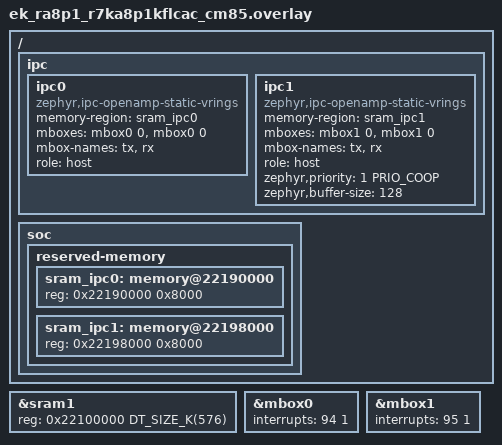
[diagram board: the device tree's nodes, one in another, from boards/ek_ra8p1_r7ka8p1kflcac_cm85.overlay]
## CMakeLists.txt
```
#
# Copyright (c) 2021 Carlo Caione <ccaione@baylibre.com>
# Copyright 2024-2026 NXP
#
# SPDX-License-Identifier: Apache-2.0
#

cmake_minimum_required(VERSION 3.28.0)

find_package(Zephyr REQUIRED HINTS $ENV{ZEPHYR_BASE})

if(CONFIG_INCLUDE_REMOTE_DIR)
set(REMOTE_ZEPHYR_DIR ${CMAKE_CURRENT_BINARY_DIR}/../remote/zephyr)
endif()

if(NOT (CONFIG_BOARD_NRF5340DK_NRF5340_CPUAPP OR
        CONFIG_BOARD_NRF5340BSIM_NRF5340_CPUAPP OR
        CONFIG_BOARD_LPCXPRESSO55S69_LPC55S69_CPU0 OR
        CONFIG_BOARD_MIMXRT1160_EVK_MIMXRT1166_CM7 OR
        CONFIG_BOARD_MIMXRT1170_EVK_MIMXRT1176_CM7 OR
        CONFIG_BOARD_MIMXRT700_EVK_MIMXRT798S_CM33_CPU0 OR
        CONFIG_BOARD_FRDM_IMXRT700_MIMXRT798S_CM33_CPU0 OR
        CONFIG_BOARD_FRDM_MCXN947_MCXN947_CPU0 OR
        CONFIG_BOARD_MCX_N9XX_EVK_MCXN947_CPU0 OR
        CONFIG_BOARD_MIMXRT1180_EVK_MIMXRT1189_CM33 OR
        CONFIG_BOARD_FRDM_IMXRT1186_MIMXRT1186_CM33 OR
        CONFIG_BOARD_EK_RA8P1_R7KA8P1KFLCAC_CM85
       )
  )
  message("${BOARD} is not supported for this sample")
endif()


project(ipc_service)

if(CONFIG_INCLUDE_REMOTE_DIR)
  target_include_directories(zephyr_interface
    INTERFACE ${REMOTE_ZEPHYR_DIR}/include/public)
endif()

target_sources(app PRIVATE src/main.c)

include(ExternalProject)
```

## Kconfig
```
# Copyright 2024 NXP
#
# SPDX-License-Identifier: Apache-2.0

source "Kconfig.zephyr"

config INCLUDE_REMOTE_DIR
	bool "Include remote core header directory"
	help
	  Include remote build header files. Can be used if primary image
	  needs to be aware of size or base address of secondary image
```

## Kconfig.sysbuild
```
# Copyright 2023 Nordic Semiconductor ASA
# Copyright 2024-2026 NXP
#
# SPDX-License-Identifier: Apache-2.0

source "share/sysbuild/Kconfig"

config NET_CORE_BOARD
string
	default "nrf5340dk/nrf5340/cpunet" if $(BOARD) = "nrf5340dk"
	default "nrf5340bsim/nrf5340/cpunet" if $(BOARD) = "nrf5340bsim"
	default "lpcxpresso55s69/lpc55s69/cpu1" if $(BOARD) = "lpcxpresso55s69"
	default "mimxrt1160_evk/mimxrt1166/cm4" if $(BOARD) = "mimxrt1160_evk"
	default "mimxrt1170_evk/mimxrt1176/cm4" if $(BOARD) = "mimxrt1170_evk"
	default "mimxrt1170_evkb/mimxrt1176/cm4" if $(BOARD) = "mimxrt1170_evkb"
	default "mimxrt700_evk/mimxrt798s/cm33_cpu1" if $(BOARD) = "mimxrt700_evk"
	default "frdm_mcxn947/mcxn947/cpu1" if $(BOARD) = "frdm_mcxn947"
	default "mcx_n9xx_evk/mcxn947/cpu1" if $(BOARD) = "mcx_n9xx_evk"
	default "mimxrt1180_evk/mimxrt1189/cm7" if "$(BOARD)/$(BOARD_QUALIFIERS)" = "mimxrt1180_evk/mimxrt1189/cm33"
	default "frdm_imxrt1186/mimxrt1186/cm7" if $(BOARD) = "frdm_imxrt1186"
	default "frdm_imxrt700/mimxrt798s/cm33_cpu1" if $(BOARD) = "frdm_imxrt700"
	default "ek_ra8p1/r7ka8p1kflcac/cm33" if $(BOARD) = "ek_ra8p1"
	default "imx943_evk/mimx94398/m33" if "$(BOARD)/$(BOARD_QUALIFIERS)" = "imx943_evk/mimx94398/m7_1"
	default "imx943_evk/mimx94398/m33" if "$(BOARD)/$(BOARD_QUALIFIERS)" = "imx943_evk/mimx94398/m7_0"
	default "imx943_evk/mimx94398/m7_1" if "$(BOARD)/$(BOARD_QUALIFIERS)" = "imx943_evk/mimx94398/m33"
```

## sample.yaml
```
sample:
  name: IPC Service example integration (OpenAMP static_vrings backend)
tests:
  sample.ipc.static_vrings:
    filter: dt_compat_enabled("zephyr,ipc-openamp-static-vrings") and
            dt_nodelabel_enabled("ipc0") and dt_nodelabel_enabled("ipc1")
    platform_exclude:
      - nrf5340dk/nrf5340/cpuapp/ns
      - nrf5340dk/nrf5340/cpunet
    integration_platforms:
      - nrf5340dk/nrf5340/cpuapp
      - nrf5340bsim/nrf5340/cpuapp
    tags: ipc
    sysbuild: true
    harness: console
    harness_config:
      type: multi_line
      ordered: false
      regex:
        - "IPC-service HOST \\[INST 0 - ENDP A\\] demo started"
        - "IPC-service HOST \\[INST 0 - ENDP B\\] demo started"
        - "IPC-service HOST \\[INST 1\\] demo started"
        - "IPC-service HOST \\[INST 0 - ENDP A\\] demo ended\\."
        - "IPC-service HOST \\[INST 0 - ENDP B\\] demo ended\\."
        - "IPC-service HOST \\[INST 1\\] demo ended\\."
```

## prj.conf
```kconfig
CONFIG_PRINTK=y
CONFIG_HEAP_MEM_POOL_SIZE=4096

CONFIG_IPC_SERVICE=y
CONFIG_MBOX=y

CONFIG_OPENAMP=y
CONFIG_OPENAMP_SLAVE=n

CONFIG_LOG=y
CONFIG_LOG_BUFFER_SIZE=4096
CONFIG_IPC_SERVICE_LOG_LEVEL_INF=y
```

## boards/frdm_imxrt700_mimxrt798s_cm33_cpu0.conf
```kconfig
# SPDX-FileCopyrightText: Copyright 2026 NXP
# SPDX-License-Identifier: Apache-2.0

CONFIG_SECOND_CORE_MCUX=y
CONFIG_INCLUDE_REMOTE_DIR=y
CONFIG_DCACHE=n
```

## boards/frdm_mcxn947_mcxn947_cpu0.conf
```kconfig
CONFIG_SECOND_CORE_MCUX=y
```

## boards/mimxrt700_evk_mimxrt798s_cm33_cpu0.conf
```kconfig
#
# Copyright 2025 NXP
#
# SPDX-License-Identifier: Apache-2.0
#

CONFIG_SECOND_CORE_MCUX=y
CONFIG_INCLUDE_REMOTE_DIR=y
CONFIG_DCACHE=n
```

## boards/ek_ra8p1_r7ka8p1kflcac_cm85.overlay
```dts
/*
 * Copyright (c) 2025-2026 Renesas Electronics Corporation
 * SPDX-License-Identifier: Apache-2.0
 */

#include <zephyr/dt-bindings/ipc_service/static_vrings.h>

/ {
	ipc {
		ipc0: ipc0 {
			compatible = "zephyr,ipc-openamp-static-vrings";
			memory-region = <&sram_ipc0>;
			mboxes = <&mbox0 0>, <&mbox0 0>;
			mbox-names = "tx", "rx";
			role = "host";
			status = "okay";
		};

		ipc1: ipc1 {
			compatible = "zephyr,ipc-openamp-static-vrings";
			memory-region = <&sram_ipc1>;
			mboxes = <&mbox1 0>, <&mbox1 0>;
			mbox-names = "tx", "rx";
			role = "host";
			zephyr,priority = <1 PRIO_COOP>;
			zephyr,buffer-size = <128>;
			status = "okay";
		};
	};

	soc {
		/* Define shared memory regions for IPC */
		reserved-memory {
			#address-cells = <1>;
			#size-cells = <1>;

			sram_ipc0: memory@22190000 {
				reg = <0x22190000 0x8000>;
			};

			sram_ipc1: memory@22198000 {
				reg = <0x22198000 0x8000>;
			};
		};
	};
};

/* Redefine sram size for CPU1 */
&sram1 {
	reg = <0x22100000 DT_SIZE_K(576)>;
};

&mbox0 {
	interrupts = <94 1>;
	status = "okay";
};

&mbox1 {
	interrupts = <95 1>;
	status = "okay";
};
```

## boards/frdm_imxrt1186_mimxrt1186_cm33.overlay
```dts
/*
 * Copyright 2026 NXP
 *
 * SPDX-License-Identifier: Apache-2.0
 */

#include <zephyr/dt-bindings/ipc_service/static_vrings.h>
#include <zephyr/dt-bindings/memory-attr/memory-attr-arm.h>

/ {
	ipc {
		/delete-node/ ipc0;

		ipc0: ipc0 {
			compatible = "zephyr,ipc-openamp-static-vrings";
			memory-region = <&ocram2_ipc0>;
			mboxes = <&mbox1_a 0>, <&mbox1_a 1>;
			mbox-names = "tx", "rx";
			role = "host";
			status = "okay";
		};

		ipc1: ipc1 {
			compatible = "zephyr,ipc-openamp-static-vrings";
			memory-region = <&ocram2_ipc1>;
			mboxes = <&mbox1_a 2>, <&mbox1_a 3>;
			mbox-names = "tx", "rx";
			role = "host";
			zephyr,priority = <1 PRIO_COOP>;
			zephyr,buffer-size = <128>;
			status = "okay";
		};
	};

	/* Define memory regions for IPC */
	ocram2_ipc0: memory@20500000 {
		compatible = "zephyr,memory-region", "mmio-sram";
		reg = <0x20500000 DT_SIZE_K(16)>;
		zephyr,memory-region = "OCRAM2_IPC0";
		zephyr,memory-attr = <DT_MEM_ARM(ATTR_MPU_IO)>;
	};

	ocram2_ipc1: memory@20504000 {
		compatible = "zephyr,memory-region", "mmio-sram";
		reg = <0x20504000 DT_SIZE_K(16)>;
		zephyr,memory-region = "OCRAM2_IPC1";
		zephyr,memory-attr = <DT_MEM_ARM(ATTR_MPU_IO)>;
	};
};
```

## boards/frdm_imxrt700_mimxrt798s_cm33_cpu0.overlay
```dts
/*
 * SPDX-FileCopyrightText: Copyright 2026 NXP
 *
 * SPDX-License-Identifier: Apache-2.0
 */

#include <zephyr/dt-bindings/ipc_service/static_vrings.h>
#include <zephyr/dt-bindings/memory-attr/memory-attr-arm.h>

/ {
	/* Define memory regions for IPC */
	sram1_ipc0: memory@20200000 {
		compatible = "zephyr,memory-region", "mmio-sram";
		reg = <0x20200000 DT_SIZE_K(16)>;
		zephyr,memory-region = "SRAM1_IPC0";
		zephyr,memory-attr = <DT_MEM_ARM(ATTR_MPU_IO)>;
	};

	sram1_ipc1: memory@20204000 {
		compatible = "zephyr,memory-region", "mmio-sram";
		reg = <0x20204000 DT_SIZE_K(16)>;
		zephyr,memory-region = "SRAM1_IPC1";
		zephyr,memory-attr = <DT_MEM_ARM(ATTR_MPU_IO)>;
	};

	ipc {
		/delete-node/ ipc0;

		ipc0: ipc0 {
			compatible = "zephyr,ipc-openamp-static-vrings";
			memory-region = <&sram1_ipc0>;
			mboxes = <&mbox1_a 0>, <&mbox1_a 1>;
			mbox-names = "tx", "rx";
			role = "host";
			status = "okay";
		};

		ipc1: ipc1 {
			compatible = "zephyr,ipc-openamp-static-vrings";
			memory-region = <&sram1_ipc1>;
			mboxes = <&mbox1_a 2>, <&mbox1_a 3>;
			mbox-names = "tx", "rx";
			role = "host";
			zephyr,priority = <1 PRIO_COOP>;
			zephyr,buffer-size = <128>;
			status = "okay";
		};
	};
};
```

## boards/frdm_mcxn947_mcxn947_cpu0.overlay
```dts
/*
 * Copyright 2024 NXP
 *
 * SPDX-License-Identifier: Apache-2.0
 */

#include <zephyr/dt-bindings/ipc_service/static_vrings.h>
#include <zephyr/dt-bindings/memory-attr/memory-attr-arm.h>

/ {
	ipc {
		/delete-node/ ipc0;

		ipc0: ipc0 {
			compatible = "zephyr,ipc-openamp-static-vrings";
			memory-region = <&sram1_ipc0>;
			mboxes = <&mbox 0>, <&mbox 1>;
			mbox-names = "tx", "rx";
			role = "host";
			status = "okay";
		};

		ipc1: ipc1 {
			compatible = "zephyr,ipc-openamp-static-vrings";
			memory-region = <&sram1_ipc1>;
			mboxes = <&mbox 2>, <&mbox 3>;
			mbox-names = "tx", "rx";
			role = "host";
			zephyr,priority = <1 PRIO_COOP>;
			zephyr,buffer-size = <128>;
			status = "okay";
		};
	};

	/* Define memory regions for IPC
	 * Note that shared memory must have specific MPU attributes set.
	 */
	sram1_ipc0: memory@20060000 {
		compatible = "zephyr,memory-region", "mmio-sram";
		reg = <0x20060000 DT_SIZE_K(16)>;
		zephyr,memory-region = "SRAM1_IPC0";
		zephyr,memory-attr = <DT_MEM_ARM(ATTR_MPU_IO)>;
	};

	sram1_ipc1: memory@20064000 {
		compatible = "zephyr,memory-region", "mmio-sram";
		reg = <0x20064000 DT_SIZE_K(16)>;
		zephyr,memory-region = "SRAM1_IPC1";
		zephyr,memory-attr = <DT_MEM_ARM(ATTR_MPU_IO)>;
	};
};
```

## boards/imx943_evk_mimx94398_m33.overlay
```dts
/*
 * Copyright 2025 NXP
 *
 * SPDX-License-Identifier: Apache-2.0
 */

#include <zephyr/dt-bindings/ipc_service/static_vrings.h>
#include <zephyr/dt-bindings/memory-attr/memory-attr-arm.h>

/ {
	ipc {
		ipc0: ipc0 {
			compatible = "zephyr,ipc-openamp-static-vrings";
			memory-region = <&dram_m33s_m71_ipc0>;
			mboxes = <&mu_m33s_m71_for_m33s 0>, <&mu_m33s_m71_for_m33s 1>;
			mbox-names = "tx", "rx";
			role = "host";
			status = "okay";
		};

		ipc1: ipc1 {
			compatible = "zephyr,ipc-openamp-static-vrings";
			memory-region = <&dram_m33s_m71_ipc1>;
			mboxes = <&mu_m33s_m71_for_m33s 2>, <&mu_m33s_m71_for_m33s 3>;
			mbox-names = "tx", "rx";
			role = "host";
			zephyr,priority = <1 PRIO_COOP>;
			zephyr,buffer-size = <128>;
			status = "okay";
		};
	};
};
```

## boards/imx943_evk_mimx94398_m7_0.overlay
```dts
/*
 * Copyright 2025 NXP
 *
 * SPDX-License-Identifier: Apache-2.0
 */

#include <zephyr/dt-bindings/ipc_service/static_vrings.h>
#include <zephyr/dt-bindings/memory-attr/memory-attr-arm.h>

/ {
	ipc {
		ipc0: ipc0 {
			compatible = "zephyr,ipc-openamp-static-vrings";
			memory-region = <&dram_m33s_m70_ipc0>;
			mboxes = <&mu_m33s_m70_for_m70 0>, <&mu_m33s_m70_for_m70 1>;
			mbox-names = "tx", "rx";
			role = "host";
			status = "okay";
		};

		ipc1: ipc1 {
			compatible = "zephyr,ipc-openamp-static-vrings";
			memory-region = <&dram_m33s_m70_ipc1>;
			mboxes = <&mu_m33s_m70_for_m70 2>, <&mu_m33s_m70_for_m70 3>;
			mbox-names = "tx", "rx";
			role = "host";
			zephyr,priority = <1 PRIO_COOP>;
			zephyr,buffer-size = <128>;
			status = "okay";
		};
	};
};
```

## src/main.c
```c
/*
 * Copyright (c) 2021 Carlo Caione <ccaione@baylibre.com>
 *
 * SPDX-License-Identifier: Apache-2.0
 */

#include <zephyr/kernel.h>
#include <zephyr/device.h>

#include <zephyr/ipc/ipc_service.h>

#define STACKSIZE	(4096)
#define PRIORITY	K_PRIO_PREEMPT(2)

K_THREAD_STACK_DEFINE(ipc0A_stack, STACKSIZE);
K_THREAD_STACK_DEFINE(ipc0B_stack, STACKSIZE);
K_THREAD_STACK_DEFINE(ipc1_stack, STACKSIZE);

static volatile uint8_t ipc0A_received_data;
static volatile uint8_t ipc0B_received_data;
static volatile uint8_t ipc1_received_data;

static K_SEM_DEFINE(ipc0A_bound_sem, 0, 1);
static K_SEM_DEFINE(ipc0B_bound_sem, 0, 1);
static K_SEM_DEFINE(ipc1_bound_sem, 0, 1);

static K_SEM_DEFINE(ipc0A_data_sem, 0, 1);
static K_SEM_DEFINE(ipc0B_data_sem, 0, 1);
static K_SEM_DEFINE(ipc1_data_sem, 0, 1);

/*
 * ==> THREAD 0A (IPC instance 0 - endpoint A) <==
 */

static void ipc0A_ept_bound(void *priv)
{
	k_sem_give(&ipc0A_bound_sem);
}

static void ipc0A_ept_recv(const void *data, size_t len, void *priv)
{
	ipc0A_received_data = *((uint8_t *) data);

	k_sem_give(&ipc0A_data_sem);
}

static struct ipc_ept_cfg ipc0A_ept_cfg = {
	.name = "ipc0A",
	.cb = {
		.bound    = ipc0A_ept_bound,
		.received = ipc0A_ept_recv,
	},
};

static void ipc0A_entry(void *dummy0, void *dummy1, void *dummy2)
{
	ARG_UNUSED(dummy0);
	ARG_UNUSED(dummy1);
	ARG_UNUSED(dummy2);

	const struct device *ipc0_instance;
	unsigned char message = 0;
	struct ipc_ept ipc0A_ept;
	int ret;

	printk("IPC-service HOST [INST 0 - ENDP A] demo started\n");

	ipc0_instance = DEVICE_DT_GET(DT_NODELABEL(ipc0));

	ret = ipc_service_open_instance(ipc0_instance);
	if (ret < 0 && ret != -EALREADY) {
		printk("ipc_service_open_instance() failure\n");
		return;
	}

	/*
	 * Wait 1 sec to give the opportunity to the SECONDARY core to register
	 * the endpoint first
	 */

	k_sleep(K_MSEC(1000));

	ret = ipc_service_register_endpoint(ipc0_instance, &ipc0A_ept, &ipc0A_ept_cfg);
	if (ret < 0) {
		printf("ipc_service_register_endpoint() failure\n");
		return;
	}

	k_sem_take(&ipc0A_bound_sem, K_FOREVER);

	while (message < 100) {
		ret = ipc_service_send(&ipc0A_ept, &message, sizeof(message));
		if (ret < 0) {
			printk("send_message(%d) failed with ret %d\n", message, ret);
			break;
		}

		k_sem_take(&ipc0A_data_sem, K_FOREVER);
		message = ipc0A_received_data;

		printk("HOST [0A]: %d\n", message);
		message++;
	}

	printk("IPC-service HOST [INST 0 - ENDP A] demo ended.\n");
}
K_THREAD_DEFINE(ipc0A_thread_id, STACKSIZE, ipc0A_entry, NULL, NULL, NULL, PRIORITY, 0, 0);

/*
 * ==> THREAD 0B (IPC instance 0 - endpoint B) <==
 */

static void ipc0B_ept_bound(void *priv)
{
	k_sem_give(&ipc0B_bound_sem);
}

static void ipc0B_ept_recv(const void *data, size_t len, void *priv)
{
	ipc0B_received_data = *((uint8_t *) data);

	k_sem_give(&ipc0B_data_sem);
}

static struct ipc_ept_cfg ipc0B_ept_cfg = {
	.name = "ipc0B",
	.cb = {
		.bound    = ipc0B_ept_bound,
		.received = ipc0B_ept_recv,
	},
};

static void ipc0B_entry(void *dummy0, void *dummy1, void *dummy2)
{
	ARG_UNUSED(dummy0);
	ARG_UNUSED(dummy1);
	ARG_UNUSED(dummy2);

	const struct device *ipc0_instance;
	unsigned char message = 0;
	struct ipc_ept ipc0B_ept;
	int ret;

	printk("IPC-service HOST [INST 0 - ENDP B] demo started\n");

	ipc0_instance = DEVICE_DT_GET(DT_NODELABEL(ipc0));

	ret = ipc_service_open_instance(ipc0_instance);
	if (ret < 0 && ret != -EALREADY) {
		printk("ipc_service_open_instance() failure\n");
		return;
	}

	ret = ipc_service_register_endpoint(ipc0_instance, &ipc0B_ept, &ipc0B_ept_cfg);
	if (ret < 0) {
		printf("ipc_service_register_endpoint() failure\n");
		return;
	}

	k_sem_take(&ipc0B_bound_sem, K_FOREVER);

	while (message < 100) {
		ret = ipc_service_send(&ipc0B_ept, &message, sizeof(message));
		if (ret < 0) {
			printk("send_message(%d) failed with ret %d\n", message, ret);
			break;
		}

		k_sem_take(&ipc0B_data_sem, K_FOREVER);
		message = ipc0B_received_data;

		printk("HOST [0B]: %d\n", message);
		message++;
	}

	printk("IPC-service HOST [INST 0 - ENDP B] demo ended.\n");
}
K_THREAD_DEFINE(ipc0B_thread_id, STACKSIZE, ipc0B_entry, NULL, NULL, NULL, PRIORITY, 0, 0);

/*
 * ==> THREAD 1 (IPC instance 1) <==
 *
 * NOTE: This instance is using the NOCOPY copability of the backend.
 */

static struct ipc_ept ipc1_ept;
static void *recv_data;

static void ipc1_ept_bound(void *priv)
{
	k_sem_give(&ipc1_bound_sem);
}

static void ipc1_ept_recv(const void *data, size_t len, void *priv)
{
	int ret;

	ret = ipc_service_hold_rx_buffer(&ipc1_ept, (void *) data);
	if (ret < 0) {
		printk("ipc_service_hold_rx_buffer failed with ret %d\n", ret);
	}

	/*
	 * This will only support a synchronous request-answer mechanism. For
	 * asynchronous cases a chain list should be implemented.
	 */
	recv_data = (void *) data;

	k_sem_give(&ipc1_data_sem);
}

static struct ipc_ept_cfg ipc1_ept_cfg = {
	.name = "ipc1",
	.cb = {
		.bound    = ipc1_ept_bound,
		.received = ipc1_ept_recv,
	},
};

static void ipc1_entry(void *dummy0, void *dummy1, void *dummy2)
{
	ARG_UNUSED(dummy0);
	ARG_UNUSED(dummy1);
	ARG_UNUSED(dummy2);

	const struct device *ipc1_instance;
	unsigned char message = 0;
	int ret;

	printk("IPC-service HOST [INST 1] demo started\n");

	ipc1_instance = DEVICE_DT_GET(DT_NODELABEL(ipc1));

	ret = ipc_service_open_instance(ipc1_instance);
	if (ret < 0 && ret != -EALREADY) {
		printk("ipc_service_open_instance() failure\n");
		return;
	}

	ret = ipc_service_register_endpoint(ipc1_instance, &ipc1_ept, &ipc1_ept_cfg);
	if (ret < 0) {
		printf("ipc_service_register_endpoint() failure\n");
		return;
	}

	k_sem_take(&ipc1_bound_sem, K_FOREVER);

	while (message < 50) {
		uint32_t len = 0;
		void *data;

		ret = ipc_service_get_tx_buffer(&ipc1_ept, &data, &len, K_FOREVER);
		if (ret < 0) {
			printk("ipc_service_get_tx_buffer failed with ret %d\n", ret);
			break;
		}

		if (message != 0) {
			*((unsigned char *) data) = *((unsigned char *) recv_data) + 1;

			ret = ipc_service_release_rx_buffer(&ipc1_ept, recv_data);
			if (ret < 0) {
				printk("ipc_service_release_rx_buffer failed with ret %d\n", ret);
				break;
			}
		} else {
			*((unsigned char *) data) = 0;
		}

		ret = ipc_service_send_nocopy(&ipc1_ept, data, sizeof(unsigned char));
		if (ret < 0) {
			printk("send_message(%d) failed with ret %d\n", message, ret);
			break;
		}

		k_sem_take(&ipc1_data_sem, K_FOREVER);

		printk("HOST [1]: %d\n", *((unsigned char *) recv_data));

		message++;
	}

	printk("IPC-service HOST [INST 1] demo ended.\n");
}
K_THREAD_DEFINE(ipc1_thread_id, STACKSIZE, ipc1_entry, NULL, NULL, NULL, PRIORITY, 0, 0);
```
